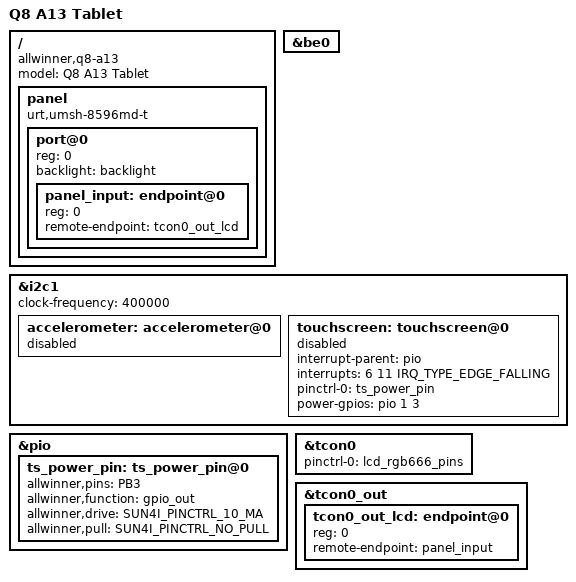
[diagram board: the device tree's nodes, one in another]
/*
 * Copyright 2015 Hans de Goede <hdegoede@redhat.com>
 *
 * This file is dual-licensed: you can use it either under the terms
 * of the GPL or the X11 license, at your option. Note that this dual
 * licensing only applies to this file, and not this project as a
 * whole.
 *
 *  a) This file is free software; you can redistribute it and/or
 *     modify it under the terms of the GNU General Public License as
 *     published by the Free Software Foundation; either version 2 of the
 *     License, or (at your option) any later version.
 *
 *     This file is distributed in the hope that it will be useful,
 *     but WITHOUT ANY WARRANTY; without even the implied warranty of
 *     MERCHANTABILITY or FITNESS FOR A PARTICULAR PURPOSE.  See the
 *     GNU General Public License for more details.
 *
 * Or, alternatively,
 *
 *  b) Permission is hereby granted, free of charge, to any person
 *     obtaining a copy of this software and associated documentation
 *     files (the "Software"), to deal in the Software without
 *     restriction, including without limitation the rights to use,
 *     copy, modify, merge, publish, distribute, sublicense, and/or
 *     sell copies of the Software, and to permit persons to whom the
 *     Software is furnished to do so, subject to the following
 *     conditions:
 *
 *     The above copyright notice and this permission notice shall be
 *     included in all copies or substantial portions of the Software.
 *
 *     THE SOFTWARE IS PROVIDED "AS IS", WITHOUT WARRANTY OF ANY KIND,
 *     EXPRESS OR IMPLIED, INCLUDING BUT NOT LIMITED TO THE WARRANTIES
 *     OF MERCHANTABILITY, FITNESS FOR A PARTICULAR PURPOSE AND
 *     NONINFRINGEMENT. IN NO EVENT SHALL THE AUTHORS OR COPYRIGHT
 *     HOLDERS BE LIABLE FOR ANY CLAIM, DAMAGES OR OTHER LIABILITY,
 *     WHETHER IN AN ACTION OF CONTRACT, TORT OR OTHERWISE, ARISING
 *     FROM, OUT OF OR IN CONNECTION WITH THE SOFTWARE OR THE USE OR
 *     OTHER DEALINGS IN THE SOFTWARE.
 */

/dts-v1/;
#include "sun5i-a13.dtsi"
#include "sun5i-reference-design-tablet.dtsi"
#include <dt-bindings/interrupt-controller/irq.h>

/ {
	model = "Q8 A13 Tablet";
	compatible = "allwinner,q8-a13", "allwinner,sun5i-a13";

	panel: panel {
		compatible = "urt,umsh-8596md-t", "simple-panel";
		#address-cells = <1>;
		#size-cells = <0>;

		port@0 {
			reg = <0>;
			/* TODO: lcd panel uses axp gpio0 as enable pin */
			backlight = <&backlight>;
			#address-cells = <1>;
			#size-cells = <0>;

			panel_input: endpoint@0 {
				reg = <0>;
				remote-endpoint = <&tcon0_out_lcd>;
			};
		};
	};
};

&be0 {
	status = "okay";
};

&i2c1 {
	/*
	 * The gsl1680 is rated at 400KHz and it will not work reliable at
	 * 100KHz, this has been confirmed on multiple different q8 tablets.
	 * The other (known) devices on this bus are all 400KHz capable.
	 */
	clock-frequency = <400000>;

	accelerometer: accelerometer@0 {
		/*
		 * Enabled by sunxi-q8-hardwaremgr if it detects a
		 * known model accelerometer.
		 */
		status = "disabled";
	};

	touchscreen: touchscreen@0 {
		interrupt-parent = <&pio>;
		interrupts = <6 11 IRQ_TYPE_EDGE_FALLING>; /* PG11 */
		pinctrl-names = "default";
		pinctrl-0 = <&ts_power_pin>;
		power-gpios = <&pio 1 3 GPIO_ACTIVE_HIGH>; /* PB3 */
		/*
		 * Enabled by sunxi-q8-hardwaremgr if it detects a
		 * known model touchscreen.
		 */
		status = "disabled";
	};
};

&pio {
	ts_power_pin: ts_power_pin@0 {
		allwinner,pins = "PB3";
		allwinner,function = "gpio_out";
		allwinner,drive = <SUN4I_PINCTRL_10_MA>;
		allwinner,pull = <SUN4I_PINCTRL_NO_PULL>;
	};
};

&tcon0 {
	pinctrl-names = "default";
	pinctrl-0 = <&lcd_rgb666_pins>;
	status = "okay";
};

&tcon0_out {
	tcon0_out_lcd: endpoint@0 {
		reg = <0>;
		remote-endpoint = <&panel_input>;
	};
};
